# ATSAMA5D26 register map
Vendor: Microchip Technology; Series: SAMA5D2; File version: 0
Registers are 32-bit, read-write, reset 0x0 unless marked. A register's access mark holds for its fields unless they carry their own. Offsets are from the block's base; [hi:lo] are bit positions; {n}, {i} and the like mark numbered series.

## SFR — Special Function Registers
Base 0xF8030000
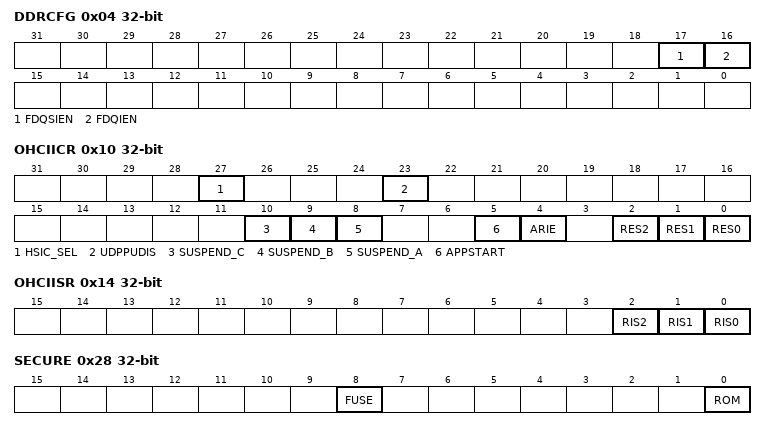
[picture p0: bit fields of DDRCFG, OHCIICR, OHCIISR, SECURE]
0x04 DDRCFG — DDR Configuration Register
  [17] FDQSIEN — Force DDR_DQS Input Buffer Always On
  [16] FDQIEN — Force DDR_DQ Input Buffer Always On
0x10 OHCIICR — OHCI Interrupt Configuration Register
  [27] HSIC_SEL
  [23] UDPPUDIS — USB DEVICE PULLUP DISABLE
  [10] SUSPEND_C — USB PORT C
  [9] SUSPEND_B — USB PORT B
  [8] SUSPEND_A — USB PORT A
  [5] APPSTART
  [4] ARIE — OHCI Asynchronous Resume Interrupt Enable
  [2] RES2 — USB PORTx RESET
  [1] RES1 — USB PORTx RESET
  [0] RES0 — USB PORTx RESET
0x14 OHCIISR ro — OHCI Interrupt Status Register
  [2] RIS2 — OHCI Resume Interrupt Status Port 2
  [1] RIS1 — OHCI Resume Interrupt Status Port 1
  [0] RIS0 — OHCI Resume Interrupt Status Port 0
0x28 SECURE — Security Configuration Register
  [8] FUSE — Disable Access to Fuse Controller
  [0] ROM — Disable Access to ROM Code
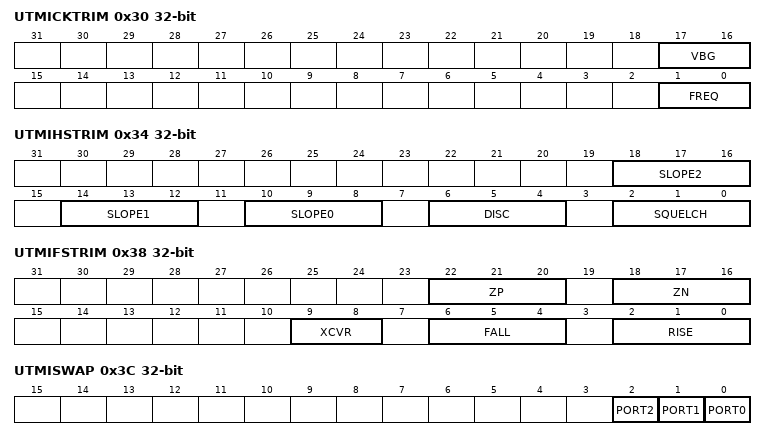
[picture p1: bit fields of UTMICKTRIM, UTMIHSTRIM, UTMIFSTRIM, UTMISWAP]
0x30 UTMICKTRIM — UTMI Clock Trimming Register
  [17:16] VBG — UTMI Band Gap Voltage Trimming
  [1:0] FREQ — UTMI Reference Clock Frequency
    0=12 MHz reference clock; 1=16 MHz reference clock; 2=24 MHz reference clock
0x34 UTMIHSTRIM — UTMI High-Speed Trimming Register
  [18:16] SLOPE2 — UTMI HS PORTx Transceiver Slope Trimming
  [14:12] SLOPE1 — UTMI HS PORTx Transceiver Slope Trimming
  [10:8] SLOPE0 — UTMI HS PORTx Transceiver Slope Trimming
  [6:4] DISC — UTMI Disconnect Voltage Trimming
  [2:0] SQUELCH — UTMI HS SQUELCH Voltage Trimming
0x38 UTMIFSTRIM — UTMI Full-Speed Trimming Register
  [22:20] ZP — FS Transceiver PMOS Impedance Trimming
  [18:16] ZN — FS Transceiver NMOS Impedance Trimming
  [9:8] XCVR — FS Transceiver Crossover Voltage Trimming
  [6:4] FALL — FS Transceiver Output Falling Slope Trimming
  [2:0] RISE — FS Transceiver Output Rising Slope Trimming
0x3C UTMISWAP — UTMI DP/DM Pin Swapping Register
  [all] fields
    0=NORMAL (DP/DM normal pinout.); 1=SWAPPED (DP/DM swapped pinout.)
  [2] PORT2 — PORT 2 DP/DM Pin Swapping
  [1] PORT1 — PORT 1 DP/DM Pin Swapping
  [0] PORT0 — PORT 0 DP/DM Pin Swapping
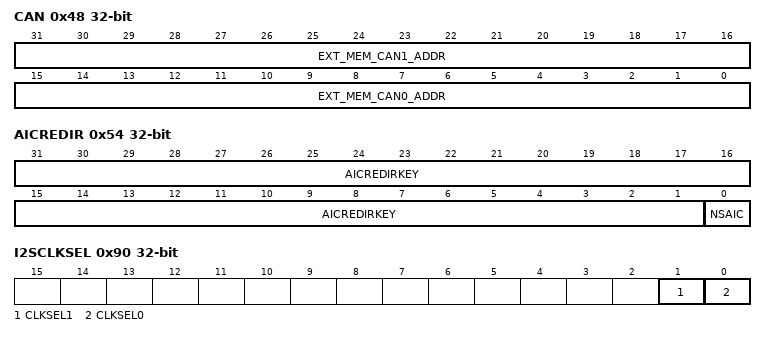
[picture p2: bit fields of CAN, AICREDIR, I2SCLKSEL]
0x48 CAN — CAN Memories Address-based Register
  [31:16] EXT_MEM_CAN1_ADDR — MSB CAN1 DMA Base Address
  [15:0] EXT_MEM_CAN0_ADDR — MSB CAN0 DMA Base Address
0x4C SN0 ro — Serial Number 0 Register
  [31:0] SN0 — Serial Number 0
0x50 SN1 ro — Serial Number 1 Register
  [31:0] SN1 — Serial Number 1
0x54 AICREDIR — AIC Interrupt Redirection Register
  [31:1] AICREDIRKEY — Unlock Key
  [0] NSAIC — Interrupt Redirection to Non-Secure AIC
0x58 L2CC_HRAMC — L2CC_HRAMC1
  [0] SRAM_SEL — SRAM Selector
0x90 I2SCLKSEL — I2SC Register
  [1] CLKSEL1 — Clock Selection 1
  [0] CLKSEL0 — Clock Selection 0
0x94 QSPICLK_REG — QSPI Clock Pad Supply Select Register
  [0] SUP_SEL — Supply Selection

## SFRBU — Special Function Registers Backup
Base 0xFC05C000
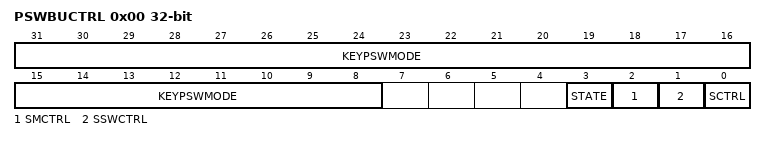
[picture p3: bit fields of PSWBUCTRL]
0x00 PSWBUCTRL — Power Switch BU Control Register
  [31:8] KEYPSWMODE
  [3] STATE — Power Switch BU state (Read-only)
  [2] SMCTRL — Allow Power Switch BU Control by Security Module Autobackup (Hardware)
  [1] SSWCTRL — Power Switch BU Source Selection
  [0] SCTRL — Power Switch BU Software Control
0x10 DDRBUMCR — DDR BU Mode Control Register
  [0] BUMEN — DDR BU Mode Enable
0x14 RXLPPUCR — RXLP Pull-Up Control Register
  [0] RXDPUCTRL — RXLP RXD Pull-Up Control

## SHA — Secure Hash Algorithm
Base 0xF0028000
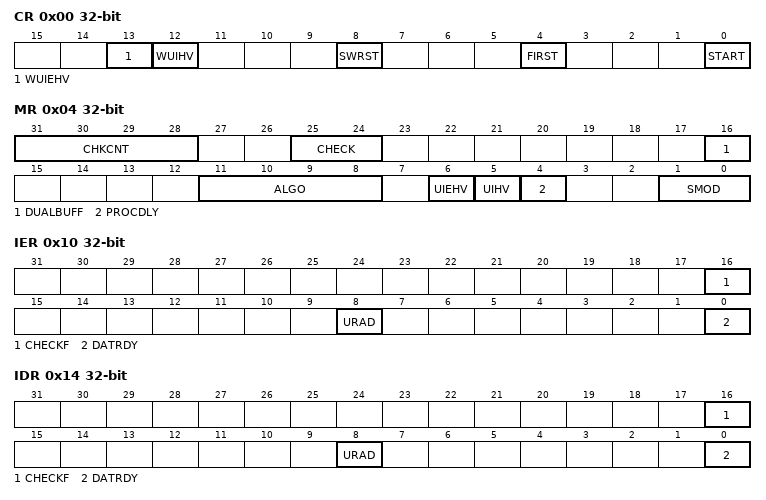
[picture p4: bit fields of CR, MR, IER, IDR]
0x00 CR wo — Control Register
  [13] WUIEHV — Write User Initial or Expected Hash Values
  [12] WUIHV — Write User Initial Hash Values
  [8] SWRST — Software Reset
  [4] FIRST — First Block of a Message
  [0] START — Start Processing
0x04 MR — Mode Register
  [31:28] CHKCNT — Check Counter
  [25:24] CHECK — Hash Check
    0=NO_CHECK (No check is performed); 1=CHECK_EHV (Check is performed with expected hash stored in internal expected hash value registers.); 2=CHECK_MESSAGE (Check is performed with expected hash provided after the message.)
  [16] DUALBUFF — Dual Input Buffer
    0=INACTIVE (SHA_IDATARx and SHA_IODATARx cannot be written during processing of previous block.); 1=ACTIVE (SHA_IDATARx and SHA_IODATARx can be written during processing of previous block when SMOD value = 2. It speeds up the overall runtime of large files.)
  [11:8] ALGO — SHA Algorithm
    0=SHA1 (SHA1 algorithm processed); 1=SHA256 (SHA256 algorithm processed); 2=SHA384 (SHA384 algorithm processed); 3=SHA512 (SHA512 algorithm processed); 4=SHA224 (SHA224 algorithm processed); 8=HMAC_SHA1 (HMAC algorithm with SHA1 Hash processed); 9=HMAC_SHA256 (HMAC algorithm with SHA256 Hash processed); 10=HMAC_SHA384 (HMAC algorithm with SHA384 Hash processed); 11=HMAC_SHA512 (HMAC algorithm with SHA512 Hash processed); 12=HMAC_SHA224 (HMAC algorithm with SHA224 Hash processed)
  [6] UIEHV — User Initial or Expected Hash Value Registers
  [5] UIHV — User Initial Hash Value Registers
  [4] PROCDLY — Processing Delay
    0=SHORTEST (SHA processing runtime is the shortest one); 1=LONGEST (SHA processing runtime is the longest one (reduces the SHA bandwidth requirement, reduces the system bus overload))
  [1:0] SMOD — Start Mode
    0=MANUAL_START (Manual mode); 1=AUTO_START (Auto mode); 2=IDATAR0_START (SHA_IDATAR0 access only mode (mandatory when DMA is used))
0x10 IER wo — Interrupt Enable Register
  [16] CHECKF — Check Done Interrupt Enable
  [8] URAD — Unspecified Register Access Detection Interrupt Enable
  [0] DATRDY — Data Ready Interrupt Enable
0x14 IDR wo — Interrupt Disable Register
  [16] CHECKF — Check Done Interrupt Disable
  [8] URAD — Unspecified Register Access Detection Interrupt Disable
  [0] DATRDY — Data Ready Interrupt Disable
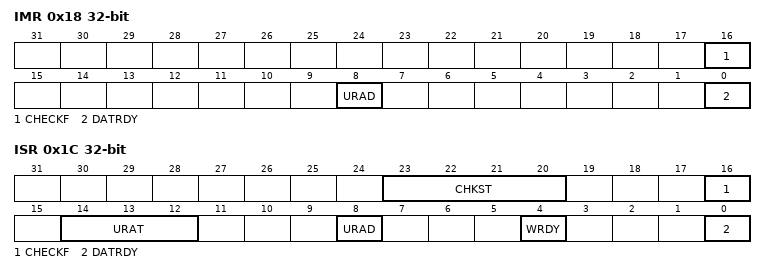
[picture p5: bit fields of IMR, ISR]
0x18 IMR ro — Interrupt Mask Register
  [16] CHECKF — Check Done Interrupt Mask
  [8] URAD — Unspecified Register Access Detection Interrupt Mask
  [0] DATRDY — Data Ready Interrupt Mask
0x1C ISR ro — Interrupt Status Register
  [23:20] CHKST — Check Status (cleared by writing START or SWRST bits in SHA_CR or by reading SHA_IODATARx)
  [16] CHECKF — Check Done Status (cleared by writing START or SWRST bits in SHA_CR or by reading SHA_IODATARx)
  [14:12] URAT — Unspecified Register Access Type (cleared by writing a 1 to SWRST bit in SHA_CR)
  [8] URAD — Unspecified Register Access Detection Status (cleared by writing a 1 to SWRST bit in SHA_CR)
  [4] WRDY — Input Data Register Write Ready
  [0] DATRDY — Data Ready (cleared by writing a 1 to bit SWRST or START in SHA_CR, or by reading SHA_IODATARx)
0x20 MSR — Message Size Register
  [31:0] MSGSIZE — Message Size
0x30 BCR — Bytes Count Register
  [31:0] BYTCNT — Remaining Byte Count Before Auto Padding
{0x40+4i} IDATAR[{i}] (i=0..15) wo — Input Data 0 Register
  [31:0] IDATA — Input Data
{0x80+4i} IODATAR[{i}] (i=0..15) — Input/Output Data 0 Register
  [31:0] IODATA — Input/Output Data
